# NAVSS0_TIMERMGR0_CFG_TIMERS register map
Vendor: Texas Instruments
Peripheral module from a debugger description file (folder am65x).
Registers are 32-bit, read-write, reset 0x0 unless marked. A register's access mark holds for its fields unless they carry their own. Offsets are as the file gives them; lines under a group give offsets from that group; [hi:lo] are bit positions; {n}, {i} and the like mark numbered series; 'fields as' and 'values as' point back to an identical list; <NAME> marks a mode.

## NAVSS0_TIMERMGR0_CFG_TIMERS
0x00 TIMERMGR_SETUP_j_k — This reprograms timer N with the written value. This number will be the number of ticks of the timer_clock before the timer expires, if timer N and the timer manager itself are both enabled via and Offset = 0h + (j * 1000h) + (k * 100h); where j = 0h to 3Fh, k = 0h to Fh
  [31:0] COUNT — The number of ticks of the timer_clock before this timer would expire when reprogrammed
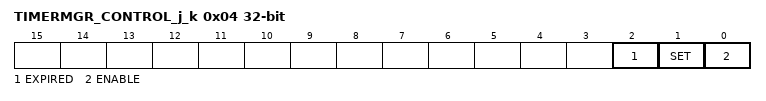
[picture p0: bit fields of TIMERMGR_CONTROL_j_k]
0x04 TIMERMGR_CONTROL_j_k access per field — Modifies the behavior of timer N with control signals below Offset = 4h + (j * 1000h) + (k * 100h); where j = 0h to 3Fh, k = 0h to Fh
  [2] EXPIRED ro — The status of the current timer. 1 = expired
  [1] SET wo — This may be used to touch/set a timer. When a 1 is written, the corresponding timer will be refreshed with the current value in its TIMERMGR_SETUP_j_k register. Will always read 0
  [0] ENABLE rw — Write 1 to enable, 0 to disable the timer.
